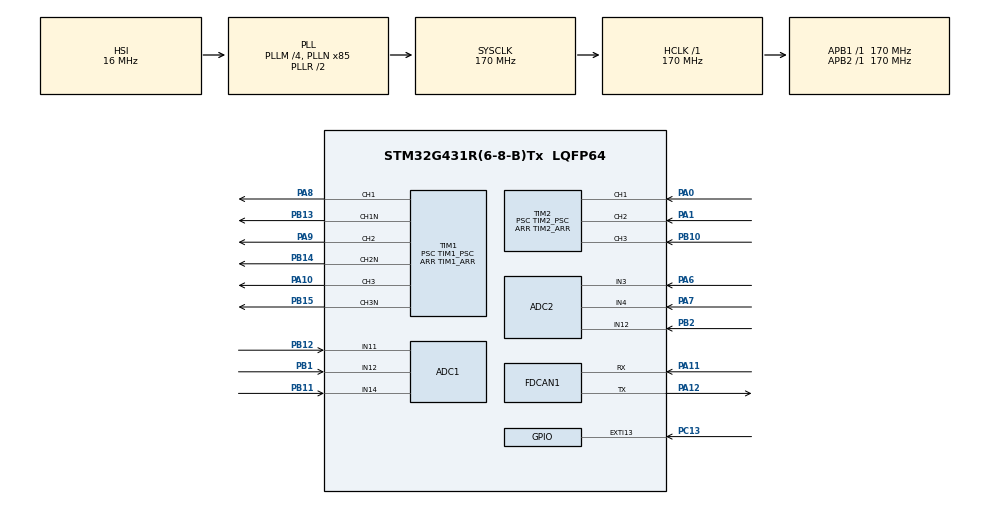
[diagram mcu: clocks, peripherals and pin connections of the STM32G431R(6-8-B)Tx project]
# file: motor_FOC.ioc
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ADC1.ContinuousConvMode=DISABLE
ADC1.DMAContinuousRequests=DISABLE
ADC1.EnableInjectedConversion=ENABLE
ADC1.EnableInjectedOversampling=DISABLE
ADC1.EnableRegularConversion=DISABLE
ADC1.ExternalTrigInjecConv=ADC_EXTERNALTRIGINJEC_T1_TRGO2
ADC1.InjNumberOfConversion=3
ADC1.InjectedChannel-6\#ChannelInjectedConversion=ADC_CHANNEL_14
ADC1.InjectedChannel-7\#ChannelInjectedConversion=ADC_CHANNEL_12
ADC1.InjectedChannel-8\#ChannelInjectedConversion=ADC_CHANNEL_11
ADC1.InjectedOffsetNumber-6\#ChannelInjectedConversion=ADC_OFFSET_NONE
ADC1.InjectedOffsetNumber-7\#ChannelInjectedConversion=ADC_OFFSET_NONE
ADC1.InjectedOffsetNumber-8\#ChannelInjectedConversion=ADC_OFFSET_NONE
ADC1.InjectedRank-6\#ChannelInjectedConversion=1
ADC1.InjectedRank-7\#ChannelInjectedConversion=2
ADC1.InjectedRank-8\#ChannelInjectedConversion=3
ADC1.InjectedSamplingTime-6\#ChannelInjectedConversion=ADC_SAMPLETIME_47CYCLES_5
ADC1.InjectedSamplingTime-7\#ChannelInjectedConversion=ADC_SAMPLETIME_47CYCLES_5
ADC1.InjectedSamplingTime-8\#ChannelInjectedConversion=ADC_SAMPLETIME_47CYCLES_5
ADC1.Mode=ADC_DUALMODE_INJECSIMULT
ADC1.Rank1_Channel=ADC_CHANNEL_14
ADC1.Rank2_Channel=ADC_CHANNEL_12
ADC1.Rank3_Channel=ADC_CHANNEL_11
ADC1.TwoSamplingDelay=ADC_TWOSAMPLINGDELAY_3CYCLES
ADC1.master=1
ADC2.EnableInjectedConversion=ENABLE
ADC2.EnableInjectedOversampling=DISABLE
ADC2.EnableRegularConversion=DISABLE
ADC2.InjNumberOfConversion=3
ADC2.InjectedChannel-2\#ChannelInjectedConversion=ADC_CHANNEL_12
ADC2.InjectedChannel-3\#ChannelInjectedConversion=ADC_CHANNEL_3
ADC2.InjectedChannel-4\#ChannelInjectedConversion=ADC_CHANNEL_4
ADC2.InjectedOffsetNumber-2\#ChannelInjectedConversion=ADC_OFFSET_NONE
ADC2.InjectedOffsetNumber-3\#ChannelInjectedConversion=ADC_OFFSET_NONE
ADC2.InjectedOffsetNumber-4\#ChannelInjectedConversion=ADC_OFFSET_NONE
ADC2.InjectedRank-2\#ChannelInjectedConversion=1
ADC2.InjectedRank-3\#ChannelInjectedConversion=2
ADC2.InjectedRank-4\#ChannelInjectedConversion=3
ADC2.InjectedSamplingTime-2\#ChannelInjectedConversion=ADC_SAMPLETIME_47CYCLES_5
ADC2.InjectedSamplingTime-3\#ChannelInjectedConversion=ADC_SAMPLETIME_47CYCLES_5
ADC2.InjectedSamplingTime-4\#ChannelInjectedConversion=ADC_SAMPLETIME_47CYCLES_5
ADC2.Mode=ADC_DUALMODE_INJECSIMULT
ADC2.Rank1_Channel=ADC_CHANNEL_12
ADC2.Rank2_Channel=ADC_CHANNEL_3
ADC2.Rank3_Channel=ADC_CHANNEL_4
ADC2.TwoSamplingDelay=ADC_TWOSAMPLINGDELAY_3CYCLES
Dma.CORDIC_READ.0.Direction=DMA_PERIPH_TO_MEMORY
Dma.CORDIC_READ.0.EventEnable=DISABLE
Dma.CORDIC_READ.0.Instance=DMA2_Channel2
Dma.CORDIC_READ.0.MemDataAlignment=DMA_MDATAALIGN_WORD
Dma.CORDIC_READ.0.MemInc=DMA_MINC_ENABLE
Dma.CORDIC_READ.0.Mode=DMA_NORMAL
Dma.CORDIC_READ.0.PeriphDataAlignment=DMA_PDATAALIGN_WORD
Dma.CORDIC_READ.0.PeriphInc=DMA_PINC_DISABLE
Dma.CORDIC_READ.0.Polarity=HAL_DMAMUX_REQ_GEN_RISING
Dma.CORDIC_READ.0.Priority=DMA_PRIORITY_LOW
Dma.CORDIC_READ.0.RequestNumber=1
Dma.CORDIC_READ.0.SignalID=NONE
Dma.CORDIC_READ.0.SyncEnable=DISABLE
Dma.CORDIC_READ.0.SyncPolarity=HAL_DMAMUX_SYNC_NO_EVENT
Dma.CORDIC_READ.0.SyncRequestNumber=1
Dma.CORDIC_READ.0.SyncSignalID=NONE
Dma.CORDIC_WRITE.1.Direction=DMA_MEMORY_TO_PERIPH
Dma.CORDIC_WRITE.1.EventEnable=DISABLE
Dma.CORDIC_WRITE.1.Instance=DMA2_Channel3
Dma.CORDIC_WRITE.1.MemDataAlignment=DMA_MDATAALIGN_WORD
Dma.CORDIC_WRITE.1.MemInc=DMA_MINC_ENABLE
Dma.CORDIC_WRITE.1.Mode=DMA_NORMAL
Dma.CORDIC_WRITE.1.PeriphDataAlignment=DMA_PDATAALIGN_WORD
Dma.CORDIC_WRITE.1.PeriphInc=DMA_PINC_DISABLE
Dma.CORDIC_WRITE.1.Polarity=HAL_DMAMUX_REQ_GEN_RISING
Dma.CORDIC_WRITE.1.Priority=DMA_PRIORITY_LOW
Dma.CORDIC_WRITE.1.RequestNumber=1
Dma.CORDIC_WRITE.1.SignalID=NONE
Dma.CORDIC_WRITE.1.SyncEnable=DISABLE
Dma.CORDIC_WRITE.1.SyncPolarity=HAL_DMAMUX_SYNC_NO_EVENT
Dma.CORDIC_WRITE.1.SyncRequestNumber=1
Dma.CORDIC_WRITE.1.SyncSignalID=NONE
Dma.Request0=CORDIC_READ
Dma.Request1=CORDIC_WRITE
FDCAN1.AutoRetransmission=ENABLE
FDCAN1.CalculateBaudRateNominal=1000000
FDCAN1.CalculateTimeBitNominal=1000
FDCAN1.CalculateTimeQuantumNominal=100.0
FDCAN1.DataPrescaler=1
FDCAN1.DataTimeSeg1=25
FDCAN1.DataTimeSeg2=8
FDCAN1.ExtFiltersNbr=FDCAN_EXT_FILTER_NBR
FDCAN1.FrameFormat=FDCAN_FRAME_FD_BRS
FDCAN1.Mode=FDCAN_MODE_NORMAL
FDCAN1.NominalPrescaler=17
FDCAN1.NominalTimeSeg1=7
FDCAN1.NominalTimeSeg2=2
FDCAN1.StdFiltersNbr=FDCAN_STD_FILTER_NBR
FREERTOS.Tasks01=defaultTask,24,512,StartDefaultTask,As weak,NULL,Dynamic,NULL,NULL
FREERTOS.configUSE_NEWLIB_REENTRANT=1
Mcu.Family=STM32G4
Mcu.Name=STM32G431R(6-8-B)Tx
Mcu.Package=LQFP64
NUCLEO-G431RB.BUTTON=1
NUCLEO-G431RB.LD1=true
NUCLEO-G431RB.VCP=true
NVIC.ADC1_2_IRQn=true\:2\:0\:true\:false\:true\:false\:true\:true\:true
NVIC.DMA2_Channel2_IRQn=true\:3\:0\:true\:false\:true\:false\:false\:true\:true
NVIC.DMA2_Channel3_IRQn=true\:3\:0\:true\:false\:true\:false\:false\:true\:true
NVIC.EXTI15_10_IRQn=true\:4\:0\:true\:false\:true\:false\:false\:true\:true
NVIC.FDCAN1_IT0_IRQn=true\:10\:0\:true\:false\:true\:true\:true\:true\:true
NVIC.FDCAN1_IT1_IRQn=true\:10\:0\:true\:false\:true\:true\:true\:true\:true
NVIC.PriorityGroup=NVIC_PRIORITYGROUP_4
NVIC.TIM1_UP_TIM16_IRQn=true\:5\:0\:false\:false\:true\:true\:true\:true\:true
NVIC.TIM2_IRQn=true\:4\:0\:true\:false\:true\:false\:true\:true\:true
NVIC.TIM6_DAC_IRQn=true\:5\:0\:false\:false\:true\:false\:false\:true\:true
NVIC.TimeBase=TIM6_DAC_IRQn
NVIC.TimeBaseIP=TIM6
PA0.GPIO_PuPd=GPIO_PULLUP
PA0.GPIO_Speed=GPIO_SPEED_FREQ_LOW
PA0.Signal=S_TIM2_CH1
PA1.GPIO_PuPd=GPIO_PULLUP
PA1.Signal=S_TIM2_CH2
PA10.GPIO_PuPd=GPIO_PULLDOWN
PA10.GPIO_Speed=GPIO_SPEED_FREQ_HIGH
PA10.Signal=S_TIM1_CH3
PA11.Mode=FDCAN_Activate
PA11.Signal=FDCAN1_RX
PA12.Mode=FDCAN_Activate
PA12.Signal=FDCAN1_TX
PA13.GPIO_Label=T_SWDIO
PA13.Signal=SYS_JTMS-SWDIO
PA14.GPIO_Label=T_SWCLK
PA14.Signal=SYS_JTCK-SWCLK
PA2.Signal=LPUART1_TX
PA3.Signal=LPUART1_RX
PA5.Signal=COMP_DAC12_group
PA6.Mode=IN3-Single-Ended
PA6.Signal=ADC2_IN3
PA7.Mode=IN4-Single-Ended
PA7.Signal=ADC2_IN4
PA8.GPIO_PuPd=GPIO_PULLDOWN
PA8.GPIO_Speed=GPIO_SPEED_FREQ_HIGH
PA8.Signal=S_TIM1_CH1
PA9.GPIO_PuPd=GPIO_PULLDOWN
PA9.GPIO_Speed=GPIO_SPEED_FREQ_HIGH
PA9.Signal=S_TIM1_CH2
PB1.Mode=IN12-Single-Ended
PB1.Signal=ADC1_IN12
PB10.GPIO_PuPd=GPIO_PULLUP
PB10.Signal=S_TIM2_CH3
PB11.Mode=IN14-Single-Ended
PB11.Signal=ADC1_IN14
PB12.Mode=IN11-Single-Ended
PB12.Signal=ADC1_IN11
PB13.GPIO_PuPd=GPIO_PULLDOWN
PB13.GPIO_Speed=GPIO_SPEED_FREQ_HIGH
PB13.Mode=PWM Generation1 CH1 CH1N
PB13.Signal=TIM1_CH1N
PB14.GPIO_PuPd=GPIO_PULLDOWN
PB14.GPIO_Speed=GPIO_SPEED_FREQ_HIGH
PB14.Mode=PWM Generation2 CH2 CH2N
PB14.Signal=TIM1_CH2N
PB15.GPIO_PuPd=GPIO_PULLDOWN
PB15.GPIO_Speed=GPIO_SPEED_FREQ_HIGH
PB15.Mode=PWM Generation3 CH3 CH3N
PB15.Signal=TIM1_CH3N
PB2.Mode=IN12-Single-Ended
PB2.Signal=ADC2_IN12
PB3.GPIO_Label=T_SWO
PB3.Signal=SYS_JTDO-SWO
PC13.Signal=GPXTI13
PC14-OSC32_IN.GPIO_Label=RCC_OSC32_OUT
PC14-OSC32_IN.Signal=RCC_OSC32_IN
PC15-OSC32_OUT.GPIO_Label=RCC_OSC32_OUT
PC15-OSC32_OUT.Signal=RCC_OSC32_OUT
PF0-OSC_IN.GPIO_Label=RCC_OSC_IN
PF0-OSC_IN.Signal=RCC_OSC_IN
PF1-OSC_OUT.GPIO_Label=RCC_OSC_OUT
PF1-OSC_OUT.Signal=RCC_OSC_OUT
ProjectManager.HeapSize=0x200
ProjectManager.StackSize=0x400
ProjectManager.TargetToolchain=STM32CubeIDE
RCC.ADC12Freq_Value=170000000
RCC.AHBFreq_Value=170000000
RCC.APB1Freq_Value=170000000
RCC.APB1TimFreq_Value=170000000
RCC.APB2Freq_Value=170000000
RCC.APB2TimFreq_Value=170000000
RCC.CortexFreq_Value=170000000
RCC.EXTERNAL_CLOCK_VALUE=12288000
RCC.HCLKFreq_Value=170000000
RCC.HSE_VALUE=24000000
RCC.HSI48_VALUE=48000000
RCC.HSI_VALUE=16000000
RCC.LSE_VALUE=32768
RCC.PLLM=RCC_PLLM_DIV4
RCC.PLLN=85
RCC.RTCClockSelection=RCC_RTCCLKSOURCE_LSE
RCC.SYSCLKFreq_VALUE=170000000
RCC.SYSCLKSource=RCC_SYSCLKSOURCE_PLLCLK
RCC.USBFreq_Value=170000000
RCC.VCOOutputFreq_Value=340000000
SH.S_TIM1_CH1.0=TIM1_CH1,PWM Generation1 CH1 CH1N
SH.S_TIM1_CH2.0=TIM1_CH2,PWM Generation2 CH2 CH2N
SH.S_TIM1_CH3.0=TIM1_CH3,PWM Generation3 CH3 CH3N
SH.S_TIM2_CH1.0=TIM2_CH1,Xored_Inputs_Hall_Sensor_Interface
SH.S_TIM2_CH2.0=TIM2_CH2,Xored_Inputs_Hall_Sensor_Interface
SH.S_TIM2_CH3.0=TIM2_CH3,Xored_Inputs_Hall_Sensor_Interface
STMicroelectronics.X-CUBE-ALGOBUILD.1.4.0.LibraryCcDSPOoLibraryJjDSPOoLibrary=true
TIM1.AutoReloadPreload=TIM_AUTORELOAD_PRELOAD_ENABLE
TIM1.AutomaticOutput=TIM_AUTOMATICOUTPUT_DISABLE
TIM1.Channel-PWM\ Generation1\ CH1\ CH1N=TIM_CHANNEL_1
TIM1.Channel-PWM\ Generation2\ CH2\ CH2N=TIM_CHANNEL_2
TIM1.Channel-PWM\ Generation3\ CH3\ CH3N=TIM_CHANNEL_3
TIM1.Channel-PWM\ Generation4\ No\ Output=TIM_CHANNEL_4
TIM1.CounterMode=TIM_COUNTERMODE_CENTERALIGNED3
TIM1.DeadTime=TIM_DTG_200ns
TIM1.DeadTimePreload=ENABLE
TIM1.OCIdleState_1=TIM_OCIDLESTATE_RESET
TIM1.OCIdleState_2=TIM_OCIDLESTATE_RESET
TIM1.OCIdleState_3=TIM_OCIDLESTATE_RESET
TIM1.OCMode_PWM-PWM\ Generation1\ CH1\ CH1N=TIM_OCMODE_PWM2
TIM1.OCMode_PWM-PWM\ Generation2\ CH2\ CH2N=TIM_OCMODE_PWM2
TIM1.OCMode_PWM-PWM\ Generation3\ CH3\ CH3N=TIM_OCMODE_PWM2
TIM1.OCNPolarity_1=TIM_OCNPOLARITY_HIGH
TIM1.OCNPolarity_2=TIM_OCNPOLARITY_HIGH
TIM1.OCNPolarity_3=TIM_OCNPOLARITY_HIGH
TIM1.OCPolarity_1=TIM_OCPOLARITY_HIGH
TIM1.OCPolarity_2=TIM_OCPOLARITY_HIGH
TIM1.OCPolarity_3=TIM_OCPOLARITY_HIGH
TIM1.OffStateIDLEMode=TIM_OSSI_ENABLE
TIM1.OffStateRunMode=TIM_OSSR_ENABLE
TIM1.PeriodNoDither=TIM1_ARR
TIM1.Prescaler=TIM1_PSC
TIM1.PulseNoDither_4=0
TIM1.TIM_MasterOutputTrigger2=TIM_TRGO2_OC4REF
TIM16.PeriodNoDither=TIM16_ARR
TIM16.Prescaler=TIM16_PSC
TIM2.ClockDivision=TIM_CLOCKDIVISION_DIV4
TIM2.IC1Filter=12
TIM2.PeriodNoDither=TIM2_ARR
TIM2.Prescaler=TIM2_PSC
VP_CORDIC_VS_CORDIC.Mode=CORDIC_Activate
VP_FREERTOS_VS_CMSIS_V2.Mode=CMSIS_V2
VP_NUCLEO-G431RB_VS_BSP_COMMON.Mode=COMMON
VP_STMicroelectronics.X-CUBE-ALGOBUILD_VS_DSPOoLibraryJjLibrary_1.4.0_1.4.0.Mode=DSPOoLibraryJjLibrary
VP_SYS_VS_DBSignals.Mode=DisableDeadBatterySignals
VP_SYS_VS_tim6.Mode=TIM6
VP_TIM16_VS_ClockSourceINT.Mode=Enable_Timer
VP_TIM1_VS_no_output4.Mode=PWM Generation4 No Output
board=NUCLEO-G431RB

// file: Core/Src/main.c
/* USER CODE BEGIN Header */
/**
  ******************************************************************************
  * @file           : main.c
  * @brief          : Main program body
  ******************************************************************************
  * @attention
  *
  * Copyright (c) 2025 STMicroelectronics.
  * All rights reserved.
  *
  * This software is licensed under terms that can be found in the LICENSE file
  * in the root directory of this software component.
  * If no LICENSE file comes with this software, it is provided AS-IS.
  *
  ******************************************************************************
  */
/* USER CODE END Header */
#include "main.h"
#include "cmsis_os.h"
#include "adc.h"
#include "cordic.h"
#include "dma.h"
#include "fdcan.h"
#include "tim.h"
#include "gpio.h"

/* USER CODE BEGIN Includes */
#include "main/_main.h"
#include "HY_MOD/main/main.h"
#include "HY_MOD/main/tim.h"
/* USER CODE END Includes */

COM_InitTypeDef BspCOMInit;

void SystemClock_Config(void);
void MX_FREERTOS_Init(void);

int main(void)
{

  /* MCU Configuration--------------------------------------------------------*/

  /* Reset of all peripherals, Initializes the Flash interface and the Systick. */
  HAL_Init();

  /* Configure the system clock */
  SystemClock_Config();

  /* Initialize all configured peripherals */
  MX_GPIO_Init();
  MX_DMA_Init();
  MX_ADC1_Init();
  MX_FDCAN1_Init();
  MX_TIM1_Init();
  MX_TIM2_Init();
  MX_CORDIC_Init();
  MX_ADC2_Init();
  MX_TIM16_Init();
  /* USER CODE BEGIN 2 */
  hymod_init();
  /* USER CODE END 2 */

  /* Init scheduler */
  osKernelInitialize();  /* Call init function for freertos objects (in cmsis_os2.c) */
  MX_FREERTOS_Init();

  /* Initialize leds */
  BSP_LED_Init(LED_GREEN);

  /* Initialize USER push-button, will be used to trigger an interrupt each time it's pressed.*/
  BSP_PB_Init(BUTTON_USER, BUTTON_MODE_EXTI);

  /* Initialize COM1 port (115200, 8 bits (7-bit data + 1 stop bit), no parity */
  BspCOMInit.BaudRate   = 115200;
  BspCOMInit.WordLength = COM_WORDLENGTH_8B;
  BspCOMInit.StopBits   = COM_STOPBITS_1;
  BspCOMInit.Parity     = COM_PARITY_NONE;
  BspCOMInit.HwFlowCtl  = COM_HWCONTROL_NONE;
  if (BSP_COM_Init(COM1, &BspCOMInit) != BSP_ERROR_NONE)
  {
    Error_Handler();
  }

  /* Start scheduler */
  osKernelStart();

  /* We should never get here as control is now taken by the scheduler */

  /* Infinite loop */
  /* USER CODE BEGIN WHILE */
  hymod_main();
  while (1)
  {

    /* USER CODE END WHILE */

  }
}

void SystemClock_Config(void)
{
  RCC_OscInitTypeDef RCC_OscInitStruct = {0};
  RCC_ClkInitTypeDef RCC_ClkInitStruct = {0};

  /** Configure the main internal regulator output voltage
  */
  HAL_PWREx_ControlVoltageScaling(PWR_REGULATOR_VOLTAGE_SCALE1_BOOST);

  /** Initializes the RCC Oscillators according to the specified parameters
  * in the RCC_OscInitTypeDef structure.
  */
  RCC_OscInitStruct.OscillatorType = RCC_OSCILLATORTYPE_HSI;
  RCC_OscInitStruct.HSIState = RCC_HSI_ON;
  RCC_OscInitStruct.HSICalibrationValue = RCC_HSICALIBRATION_DEFAULT;
  RCC_OscInitStruct.PLL.PLLState = RCC_PLL_ON;
  RCC_OscInitStruct.PLL.PLLSource = RCC_PLLSOURCE_HSI;
  RCC_OscInitStruct.PLL.PLLM = RCC_PLLM_DIV4;
  RCC_OscInitStruct.PLL.PLLN = 85;
  RCC_OscInitStruct.PLL.PLLP = RCC_PLLP_DIV2;
  RCC_OscInitStruct.PLL.PLLQ = RCC_PLLQ_DIV2;
  RCC_OscInitStruct.PLL.PLLR = RCC_PLLR_DIV2;
  if (HAL_RCC_OscConfig(&RCC_OscInitStruct) != HAL_OK)
  {
    Error_Handler();
  }

  /** Initializes the CPU, AHB and APB buses clocks
  */
  RCC_ClkInitStruct.ClockType = RCC_CLOCKTYPE_HCLK|RCC_CLOCKTYPE_SYSCLK
                              |RCC_CLOCKTYPE_PCLK1|RCC_CLOCKTYPE_PCLK2;
  RCC_ClkInitStruct.SYSCLKSource = RCC_SYSCLKSOURCE_PLLCLK;
  RCC_ClkInitStruct.AHBCLKDivider = RCC_SYSCLK_DIV1;
  RCC_ClkInitStruct.APB1CLKDivider = RCC_HCLK_DIV1;
  RCC_ClkInitStruct.APB2CLKDivider = RCC_HCLK_DIV1;

  if (HAL_RCC_ClockConfig(&RCC_ClkInitStruct, FLASH_LATENCY_4) != HAL_OK)
  {
    Error_Handler();
  }
}

void HAL_TIM_PeriodElapsedCallback(TIM_HandleTypeDef *htim)
{
  if (htim->Instance == TIM6)
  {
    HAL_IncTick();
  }
  /* USER CODE BEGIN Callback 1 */
  HAL_TIM_PeriodElapsedCallback_OWN(htim);
  /* USER CODE END Callback 1 */
}

void Error_Handler(void)
{
  __disable_irq();
  while (1)
  {
  }
}

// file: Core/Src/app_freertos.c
/* USER CODE BEGIN Header */
/**
  ******************************************************************************
  * File Name          : app_freertos.c
  * Description        : Code for freertos applications
  ******************************************************************************
  * @attention
  *
  * Copyright (c) 2025 STMicroelectronics.
  * All rights reserved.
  *
  * This software is licensed under terms that can be found in the LICENSE file
  * in the root directory of this software component.
  * If no LICENSE file comes with this software, it is provided AS-IS.
  *
  ******************************************************************************
  */
/* USER CODE END Header */

#include "FreeRTOS.h"
#include "task.h"
#include "main.h"
#include "cmsis_os.h"

/* Definitions for defaultTask */
osThreadId_t defaultTaskHandle;
const osThreadAttr_t defaultTask_attributes = {
  .name = "defaultTask",
  .priority = (osPriority_t) osPriorityNormal,
  .stack_size = 128 * 4
};
/* Definitions for motorTask */
osThreadId_t motorTaskHandle;
const osThreadAttr_t motorTask_attributes = {
  .name = "motorTask",
  .priority = (osPriority_t) osPriorityAboveNormal,
  .stack_size = 128 * 4
};

void StartDefaultTask(void *argument);
void StartMotorTask(void *argument);

void MX_FREERTOS_Init(void); /* (MISRA C 2004 rule 8.1) */

void MX_FREERTOS_Init(void) {

  /* Create the thread(s) */
  /* creation of defaultTask */
  defaultTaskHandle = osThreadNew(StartDefaultTask, NULL, &defaultTask_attributes);

  /* creation of motorTask */
  motorTaskHandle = osThreadNew(StartMotorTask, NULL, &motorTask_attributes);

}

__weak void StartDefaultTask(void *argument)
{
  for(;;)
  {
    osDelay(1);
  }
}

__weak void StartMotorTask(void *argument)
{
  for(;;)
  {
    osDelay(1);
  }
}
